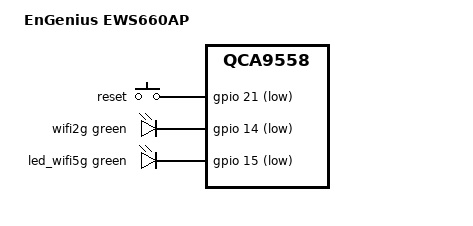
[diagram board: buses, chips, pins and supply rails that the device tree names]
// SPDX-License-Identifier: GPL-2.0-or-later OR MIT

#include "qca9558_engenius_dual_ap.dtsi"

#include <dt-bindings/gpio/gpio.h>
#include <dt-bindings/input/input.h>
#include <dt-bindings/leds/common.h>

/ {
	compatible = "engenius,ews660ap", "qca,qca9558";
	model = "EnGenius EWS660AP";

	aliases {
		label-mac-device = &eth0;
		led-boot = &led_wifi5g;
		led-failsafe = &led_wifi5g;
		led-upgrade = &led_wifi5g;
	};

	keys {
		compatible = "gpio-keys";

		reset {
			label = "reset";
			gpios = <&gpio 21 GPIO_ACTIVE_LOW>;
			debounce-interval = <60>;
			linux,code = <KEY_RESTART>;
		};
	};

	leds {
		compatible = "gpio-leds";

		wifi2g {
			color = <LED_COLOR_ID_GREEN>;
			function = LED_FUNCTION_WLAN_2GHZ;
			gpios = <&gpio 14 GPIO_ACTIVE_LOW>;
			linux,default-trigger = "phy1tpt";
		};

		led_wifi5g: wifi5g {
			color = <LED_COLOR_ID_GREEN>;
			function = LED_FUNCTION_WLAN_5GHZ;
			gpios = <&gpio 15 GPIO_ACTIVE_LOW>;
			linux,default-trigger = "phy0tpt";
		};
	};
};
